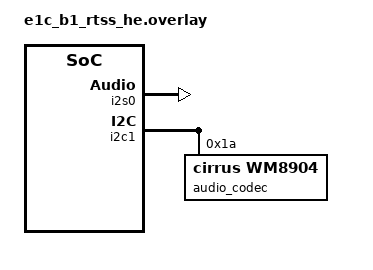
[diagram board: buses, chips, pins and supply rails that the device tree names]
/*
 * Copyright (c) 2025 Titouan Christophe
 * SPDX-License-Identifier: Apache-2.0
 */

/ {
        aliases {
                i2s-codec-tx = &i2s0;
        };
};

&i2s0{
        status ="okay";
};


&pinctrl {
	pinctrl_i2s0:pinctrl_i2s0 {
		group0 {
			pinmux = < PIN_P2_4__I2S0_SDI_B >,
				< PIN_P2_5__I2S0_SDO_B >,
				< PIN_P1_6__I2S0_SCLK_A >,
				< PIN_P1_7__I2S0_WS_A >;
		};
	};
};



&i2c1 {
	/*clock-frequency = <I2C_BITRATE_STANDARD>;*/
	status = "okay";

	audio_codec: wm8904@1a {
		compatible = "cirrus,wm8904";
		reg = <0x1a>;
		status = "okay";
	};
};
